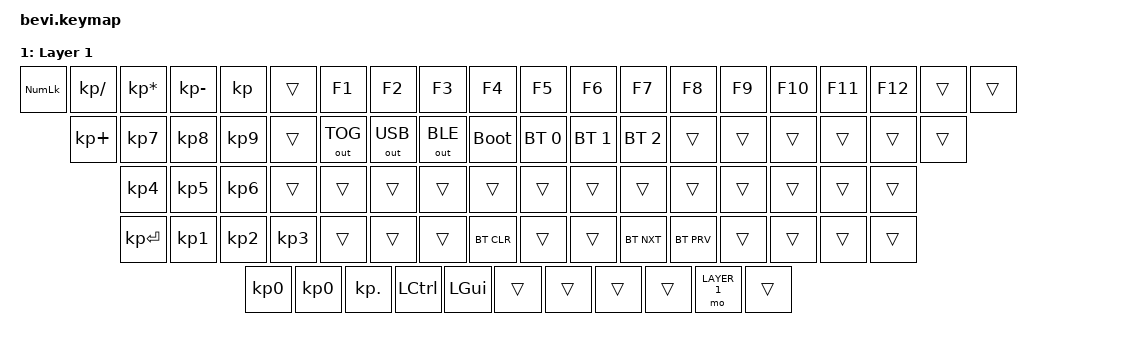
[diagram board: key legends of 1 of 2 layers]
#include <behaviors.dtsi>
#include <dt-bindings/zmk/keys.h>
#include <dt-bindings/zmk/bt.h>
#include <dt-bindings/zmk/outputs.h>

#define LAYER_1 1
/ {
    keymap {
        compatible = "zmk,keymap";

        default_layer {
            label = "Default";
            bindings = <
       &kp ESC  &kp C_MUTE  &kp C_VOLUME_DOWN  &kp C_VOLUME_UP  &kp GRAVE   &kp NUMBER_1     &kp NUMBER_2     &kp NUMBER_3     &kp NUMBER_4     &kp NUMBER_5     &kp NUMBER_6     &kp NUMBER_7     &kp NUMBER_8     &kp NUMBER_9     &kp NUMBER_0     &kp MINUS  &kp EQL   &kp BSPC  &kp DEL  
       &kp KP_PLUS  &kp INSERT    &kp HOME    &kp PAGE_UP    &kp TAB   &kp Q     &kp W     &kp E     &kp R     &kp T     &kp Y     &kp U     &kp I     &kp O     &kp P     &kp LBKT  &kp RBKT      &kp BSLH      
                   &kp DELETE    &kp END    &kp PAGE_DOWN    &kp CAPS    &kp A     &kp S     &kp D     &kp F     &kp G     &kp H     &kp J     &kp K     &kp L     &kp SCLN  &kp QUOT           &kp ENTER        
       &kp KP_ENTER  &kp LSFT    &kp UP_ARROW    &mo LAYER_1    &kp LSFT     &kp Z     &kp X     &kp C     &kp V     &kp B     &kp N     &kp M     &kp COMMA  &kp DOT   &kp SLASH      &kp RSFT                     
                   &kp LEFT_ARROW    &kp DOWN_ARROW    &kp RIGHT_ARROW  &kp LCTL  &kp LGUI  &kp LALT                                      &kp SPC                               &kp RALT  &kp RGUI &mo LAYER_1 &kp RCTL  
            >;
        };
        layer1_layer {
            label = "Layer 1";
            bindings = <
       &kp KP_NLCK  &kp KP_DIVIDE  &kp KP_MULTIPLY  &kp KP_MINUS  &kp &trans   &kp F1     &kp F2     &kp F3     &kp F4     &kp F5     &kp F6    &kp F7     &kp F8     &kp F9     &kp F10     &kp F11  &kp F12   &trans  &trans  
       &kp KP_PLUS  &kp KP_NUMBER_7    &kp KP_NUMBER_8    &kp KP_NUMBER_9    &trans   &out OUT_TOG     &out OUT_USB     &out OUT_BLE     &bootloader     &bt BT_SEL 0     &bt BT_SEL 1     &bt BT_SEL 2     &trans     &trans     &trans     &trans  &trans      &trans      
                   &kp KP_NUMBER_4    &kp KP_NUMBER_5    &kp KP_NUMBER_6    &trans    &trans     &trans     &trans     &trans     &trans     &trans     &trans     &trans     &trans     &trans  &trans           &trans        
       &kp KP_ENTER  &kp KP_NUMBER_1    &kp KP_NUMBER_2    &kp KP_NUMBER_3    &trans     &trans     &trans     &bt BT_CLR     &trans     &trans     &bt BT_NXT     &bt BT_PRV     &trans  &trans   &trans    &trans                     
                   &kp KP_NUMBER_0    &kp KP_NUMBER_0    &kp KP_DOT  &kp LCTL  &kp LGUI  &trans                                      &trans                               &trans  &trans &mo LAYER_1 &trans  
            >;
        };
    };
};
